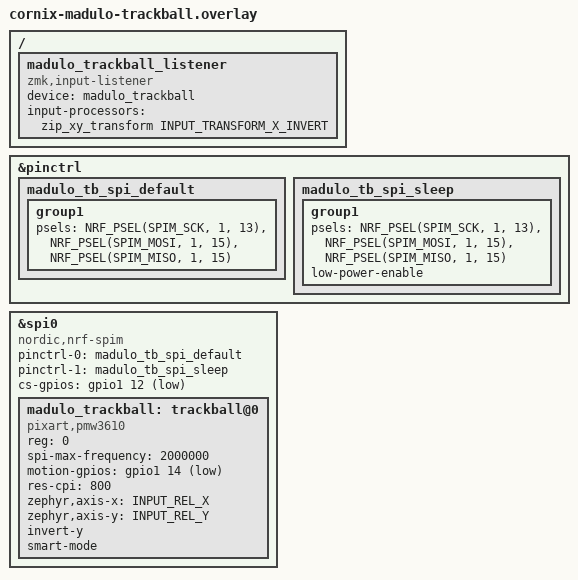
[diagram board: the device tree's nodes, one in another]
#include <dt-bindings/gpio/gpio.h>
#include <dt-bindings/zmk/input_transform.h>
#include <zephyr/dt-bindings/input/input-event-codes.h>
#include <input/processors.dtsi>

&pinctrl {
    madulo_tb_spi_default: madulo_tb_spi_default {
        group1 {
            psels = <NRF_PSEL(SPIM_SCK,  1, 13)>,
                    <NRF_PSEL(SPIM_MOSI, 1, 15)>,
                    <NRF_PSEL(SPIM_MISO, 1, 15)>;
        };
    };

    madulo_tb_spi_sleep: madulo_tb_spi_sleep {
        group1 {
            psels = <NRF_PSEL(SPIM_SCK,  1, 13)>,
                    <NRF_PSEL(SPIM_MOSI, 1, 15)>,
                    <NRF_PSEL(SPIM_MISO, 1, 15)>;
            low-power-enable;
        };
    };
};

/ {
    madulo_trackball_listener: madulo_trackball_listener {
        compatible = "zmk,input-listener";
        device = <&madulo_trackball>;
        input-processors = <&zip_xy_transform INPUT_TRANSFORM_X_INVERT>;
    };
};

&spi0 {
    status = "okay";
    compatible = "nordic,nrf-spim";
    pinctrl-0 = <&madulo_tb_spi_default>;
    pinctrl-1 = <&madulo_tb_spi_sleep>;
    pinctrl-names = "default", "sleep";
    cs-gpios = <&gpio1 12 GPIO_ACTIVE_LOW>;

    madulo_trackball: trackball@0 {
        status = "okay";
        compatible = "pixart,pmw3610";
        reg = <0>;
        spi-max-frequency = <2000000>;
        motion-gpios = <&gpio1 14 (GPIO_ACTIVE_LOW | GPIO_PULL_UP)>;
        res-cpi = <800>;
        zephyr,axis-x = <INPUT_REL_X>;
        zephyr,axis-y = <INPUT_REL_Y>;
        invert-y;
        smart-mode;
    };
};
